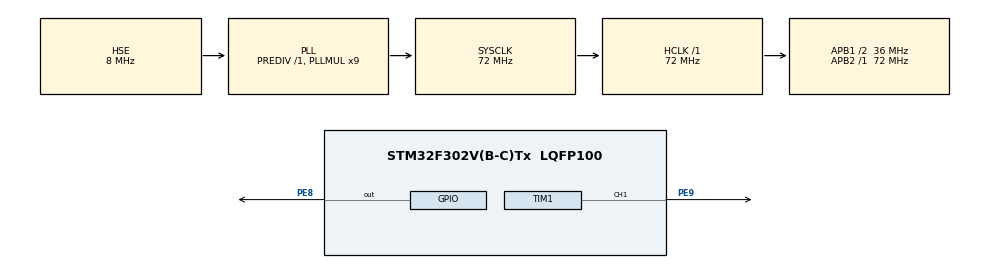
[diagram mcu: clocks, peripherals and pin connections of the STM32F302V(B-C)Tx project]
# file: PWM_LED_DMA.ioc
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Dma.Request0=TIM1_CH1
Dma.TIM1_CH1.0.Direction=DMA_MEMORY_TO_PERIPH
Dma.TIM1_CH1.0.Instance=DMA1_Channel2
Dma.TIM1_CH1.0.MemDataAlignment=DMA_MDATAALIGN_HALFWORD
Dma.TIM1_CH1.0.MemInc=DMA_MINC_ENABLE
Dma.TIM1_CH1.0.Mode=DMA_NORMAL
Dma.TIM1_CH1.0.PeriphDataAlignment=DMA_PDATAALIGN_HALFWORD
Dma.TIM1_CH1.0.PeriphInc=DMA_PINC_DISABLE
Dma.TIM1_CH1.0.Priority=DMA_PRIORITY_LOW
Mcu.Family=STM32F3
Mcu.Name=STM32F302V(B-C)Tx
Mcu.Package=LQFP100
NVIC.DMA1_Channel2_IRQn=true\:0\:0\:false\:false\:true\:false\:true
NVIC.PriorityGroup=NVIC_PRIORITYGROUP_4
PE8.Signal=GPIO_Output
PE9.Signal=S_TIM1_CH1
PF0-OSC_IN.Mode=HSE-External-Oscillator
PF0-OSC_IN.Signal=RCC_OSC_IN
PF1-OSC_OUT.Mode=HSE-External-Oscillator
PF1-OSC_OUT.Signal=RCC_OSC_OUT
ProjectManager.HeapSize=0x200
ProjectManager.StackSize=0x400
ProjectManager.TargetToolchain=STM32CubeIDE
RCC.AHBFreq_Value=72000000
RCC.APB1CLKDivider=RCC_HCLK_DIV2
RCC.APB1Freq_Value=36000000
RCC.APB1TimFreq_Value=72000000
RCC.APB2Freq_Value=72000000
RCC.APB2TimFreq_Value=72000000
RCC.CortexFreq_Value=72000000
RCC.HCLKFreq_Value=72000000
RCC.HSE_VALUE=8000000
RCC.HSI_VALUE=8000000
RCC.LSE_VALUE=32768
RCC.PLLMUL=RCC_PLL_MUL9
RCC.PLLSourceVirtual=RCC_PLLSOURCE_HSE
RCC.SYSCLKFreq_VALUE=72000000
RCC.SYSCLKSourceVirtual=RCC_SYSCLKSOURCE_PLLCLK
RCC.USBFreq_Value=72000000
SH.S_TIM1_CH1.0=TIM1_CH1,PWM Generation1 CH1
TIM1.Channel-PWM\ Generation1\ CH1=TIM_CHANNEL_1
VP_TIM1_VS_ClockSourceINT.Mode=Internal
board=custom

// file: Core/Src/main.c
/* USER CODE BEGIN Header */
/**
  ******************************************************************************
  * @file           : main.c
  * @brief          : Main program body
  ******************************************************************************
  * @attention
  *
  * <h2><center>&copy; Copyright (c) 2021 STMicroelectronics.
  * All rights reserved.</center></h2>
  *
  * This software component is licensed by ST under BSD 3-Clause license,
  * the "License"; You may not use this file except in compliance with the
  * License. You may obtain a copy of the License at:
  *                        opensource.org/licenses/BSD-3-Clause
  *
  ******************************************************************************
  */
/* USER CODE END Header */
#include "main.h"

/* USER CODE BEGIN PD */
#define ONE_PULSE 85
#define ZERO_PULSE 36
/* USER CODE END PD */

TIM_HandleTypeDef htim1;
DMA_HandleTypeDef hdma_tim1_ch1;

/* USER CODE BEGIN PV */
uint16_t Duty[24] = {ONE_PULSE, ONE_PULSE, ONE_PULSE, ONE_PULSE, ONE_PULSE, ONE_PULSE, ONE_PULSE, ONE_PULSE,
					ZERO_PULSE, ZERO_PULSE, ZERO_PULSE, ZERO_PULSE, ZERO_PULSE, ZERO_PULSE, ZERO_PULSE, ZERO_PULSE,
					ZERO_PULSE, ZERO_PULSE, ZERO_PULSE, ZERO_PULSE, ZERO_PULSE, ZERO_PULSE, ZERO_PULSE, ZERO_PULSE};
uint8_t counter = 0;
/* USER CODE END PV */

void SystemClock_Config(void);
static void MX_GPIO_Init(void);
static void MX_DMA_Init(void);
static void MX_TIM1_Init(void);

/* USER CODE BEGIN 0 */
void HAL_TIM_PWM_PulseFinishedCallback(TIM_HandleTypeDef *htim)
{
		HAL_TIM_PWM_Stop_DMA(&htim1, TIM_CHANNEL_1);

}

void send()
{
	HAL_TIM_PWM_Start_DMA(&htim1, TIM_CHANNEL_1, (uint32_t *)Duty, 24);
}
/* USER CODE END 0 */

int main(void)
{

  /* MCU Configuration--------------------------------------------------------*/

  /* Reset of all peripherals, Initializes the Flash interface and the Systick. */
  HAL_Init();

  /* Configure the system clock */
  SystemClock_Config();

  /* Initialize all configured peripherals */
  MX_GPIO_Init();
  MX_DMA_Init();
  MX_TIM1_Init();
  /* USER CODE BEGIN 2 */
  //HAL_TIM_PWM_Start_DMA(&htim1, TIM_CHANNEL_1, 15000, 1);
  send();
  HAL_GPIO_WritePin(GPIOE, GPIO_PIN_8, GPIO_PIN_SET);
  /* USER CODE END 2 */

  /* Infinite loop */
  while (1)
  {

  }
}

void SystemClock_Config(void)
{
  RCC_OscInitTypeDef RCC_OscInitStruct = {0};
  RCC_ClkInitTypeDef RCC_ClkInitStruct = {0};
  RCC_PeriphCLKInitTypeDef PeriphClkInit = {0};

  /** Initializes the RCC Oscillators according to the specified parameters
  * in the RCC_OscInitTypeDef structure.
  */
  RCC_OscInitStruct.OscillatorType = RCC_OSCILLATORTYPE_HSE;
  RCC_OscInitStruct.HSEState = RCC_HSE_ON;
  RCC_OscInitStruct.HSEPredivValue = RCC_HSE_PREDIV_DIV1;
  RCC_OscInitStruct.HSIState = RCC_HSI_ON;
  RCC_OscInitStruct.PLL.PLLState = RCC_PLL_ON;
  RCC_OscInitStruct.PLL.PLLSource = RCC_PLLSOURCE_HSE;
  RCC_OscInitStruct.PLL.PLLMUL = RCC_PLL_MUL9;
  if (HAL_RCC_OscConfig(&RCC_OscInitStruct) != HAL_OK)
  {
    Error_Handler();
  }
  /** Initializes the CPU, AHB and APB buses clocks
  */
  RCC_ClkInitStruct.ClockType = RCC_CLOCKTYPE_HCLK|RCC_CLOCKTYPE_SYSCLK
                              |RCC_CLOCKTYPE_PCLK1|RCC_CLOCKTYPE_PCLK2;
  RCC_ClkInitStruct.SYSCLKSource = RCC_SYSCLKSOURCE_PLLCLK;
  RCC_ClkInitStruct.AHBCLKDivider = RCC_SYSCLK_DIV1;
  RCC_ClkInitStruct.APB1CLKDivider = RCC_HCLK_DIV2;
  RCC_ClkInitStruct.APB2CLKDivider = RCC_HCLK_DIV1;

  if (HAL_RCC_ClockConfig(&RCC_ClkInitStruct, FLASH_LATENCY_2) != HAL_OK)
  {
    Error_Handler();
  }
  PeriphClkInit.PeriphClockSelection = RCC_PERIPHCLK_TIM1;
  PeriphClkInit.Tim1ClockSelection = RCC_TIM1CLK_HCLK;
  if (HAL_RCCEx_PeriphCLKConfig(&PeriphClkInit) != HAL_OK)
  {
    Error_Handler();
  }
}

static void MX_TIM1_Init(void)
{

  TIM_ClockConfigTypeDef sClockSourceConfig = {0};
  TIM_MasterConfigTypeDef sMasterConfig = {0};
  TIM_OC_InitTypeDef sConfigOC = {0};
  TIM_BreakDeadTimeConfigTypeDef sBreakDeadTimeConfig = {0};

  htim1.Instance = TIM1;
  htim1.Init.Prescaler = 0;
  htim1.Init.CounterMode = TIM_COUNTERMODE_UP;
  htim1.Init.Period = 179;
  htim1.Init.ClockDivision = TIM_CLOCKDIVISION_DIV1;
  htim1.Init.RepetitionCounter = 0;
  htim1.Init.AutoReloadPreload = TIM_AUTORELOAD_PRELOAD_DISABLE;
  if (HAL_TIM_Base_Init(&htim1) != HAL_OK)
  {
    Error_Handler();
  }
  sClockSourceConfig.ClockSource = TIM_CLOCKSOURCE_INTERNAL;
  if (HAL_TIM_ConfigClockSource(&htim1, &sClockSourceConfig) != HAL_OK)
  {
    Error_Handler();
  }
  if (HAL_TIM_PWM_Init(&htim1) != HAL_OK)
  {
    Error_Handler();
  }
  sMasterConfig.MasterOutputTrigger = TIM_TRGO_RESET;
  sMasterConfig.MasterOutputTrigger2 = TIM_TRGO2_RESET;
  sMasterConfig.MasterSlaveMode = TIM_MASTERSLAVEMODE_DISABLE;
  if (HAL_TIMEx_MasterConfigSynchronization(&htim1, &sMasterConfig) != HAL_OK)
  {
    Error_Handler();
  }
  sConfigOC.OCMode = TIM_OCMODE_PWM1;
  sConfigOC.Pulse = 0;
  sConfigOC.OCPolarity = TIM_OCPOLARITY_HIGH;
  sConfigOC.OCNPolarity = TIM_OCNPOLARITY_HIGH;
  sConfigOC.OCFastMode = TIM_OCFAST_DISABLE;
  sConfigOC.OCIdleState = TIM_OCIDLESTATE_RESET;
  sConfigOC.OCNIdleState = TIM_OCNIDLESTATE_RESET;
  if (HAL_TIM_PWM_ConfigChannel(&htim1, &sConfigOC, TIM_CHANNEL_1) != HAL_OK)
  {
    Error_Handler();
  }
  sBreakDeadTimeConfig.OffStateRunMode = TIM_OSSR_DISABLE;
  sBreakDeadTimeConfig.OffStateIDLEMode = TIM_OSSI_DISABLE;
  sBreakDeadTimeConfig.LockLevel = TIM_LOCKLEVEL_OFF;
  sBreakDeadTimeConfig.DeadTime = 0;
  sBreakDeadTimeConfig.BreakState = TIM_BREAK_DISABLE;
  sBreakDeadTimeConfig.BreakPolarity = TIM_BREAKPOLARITY_HIGH;
  sBreakDeadTimeConfig.BreakFilter = 0;
  sBreakDeadTimeConfig.Break2State = TIM_BREAK2_DISABLE;
  sBreakDeadTimeConfig.Break2Polarity = TIM_BREAK2POLARITY_HIGH;
  sBreakDeadTimeConfig.Break2Filter = 0;
  sBreakDeadTimeConfig.AutomaticOutput = TIM_AUTOMATICOUTPUT_DISABLE;
  if (HAL_TIMEx_ConfigBreakDeadTime(&htim1, &sBreakDeadTimeConfig) != HAL_OK)
  {
    Error_Handler();
  }
  HAL_TIM_MspPostInit(&htim1);

}

static void MX_DMA_Init(void)
{

  /* DMA controller clock enable */
  __HAL_RCC_DMA1_CLK_ENABLE();

  /* DMA interrupt init */
  /* DMA1_Channel2_IRQn interrupt configuration */
  HAL_NVIC_SetPriority(DMA1_Channel2_IRQn, 0, 0);
  HAL_NVIC_EnableIRQ(DMA1_Channel2_IRQn);

}

static void MX_GPIO_Init(void)
{
  GPIO_InitTypeDef GPIO_InitStruct = {0};

  /* GPIO Ports Clock Enable */
  __HAL_RCC_GPIOF_CLK_ENABLE();
  __HAL_RCC_GPIOE_CLK_ENABLE();

  /*Configure GPIO pin Output Level */
  HAL_GPIO_WritePin(GPIOE, GPIO_PIN_8, GPIO_PIN_RESET);

  /*Configure GPIO pin : PE8 */
  GPIO_InitStruct.Pin = GPIO_PIN_8;
  GPIO_InitStruct.Mode = GPIO_MODE_OUTPUT_PP;
  GPIO_InitStruct.Pull = GPIO_NOPULL;
  GPIO_InitStruct.Speed = GPIO_SPEED_FREQ_LOW;
  HAL_GPIO_Init(GPIOE, &GPIO_InitStruct);

}

void Error_Handler(void)
{
  __disable_irq();
  while (1)
  {
  }
}

/************************ (C) COPYRIGHT STMicroelectronics *****END OF FILE****/
